# SAMA7D65D1GN2 register map
Vendor: Microchip Technology; Series: SAMA7D6; File version: 0
Registers are 32-bit, read-write, reset 0x0 unless marked. A register's access mark holds for its fields unless they carry their own. Offsets are from the block's base; [hi:lo] are bit positions; lines under a group give offsets from that group; {n}, {i} and the like mark numbered series.

## SYSCWP — System Controller Write Protection
Base 0xE001D900
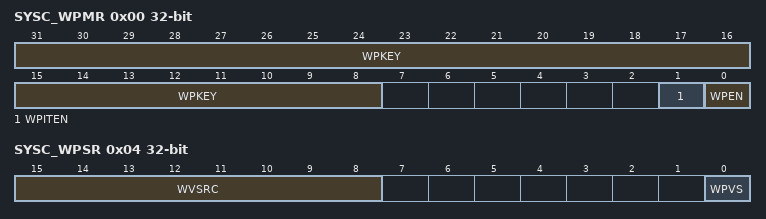
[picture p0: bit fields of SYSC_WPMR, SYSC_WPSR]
0x00 SYSC_WPMR — Write Protection Mode Register
  [31:8] WPKEY — Write Protection Key
    0x535943=PASSWD (Writing any other value in this field aborts the write operation of the WPEN and WPITEN bits. Always reads as 0.)
  [1] WPITEN — Write Protection RTC Interrupt Enable
    0=Disables the write protection of the RTC_IER/RTC_IDR configuration registers if WPKEY corresponds to 0x535943 ('SYC' in ASCII); 1=Enables the write protection of the RTC_IER/RTC_IDR configuration registers if WPKEY corresponds to 0x535943 ('SYC' in ASCII)
  [0] WPEN — Write Protection Enable
    0=Disables the write protection of the configuration registers if WPKEY corresponds to 0x535943 ('SYC' in ASCII); 1=Enables the write protection of the configuration registers if WPKEY corresponds to 0x535943 ('SYC' in ASCII)
0x04 SYSC_WPSR ro — Write Protection Status Register
  [15:8] WVSRC — Write Violation Source
  [0] WPVS — Write Protection Register Violation Status
    0=No write protection violation has occurred since the last read of SYSC_WPSR; 1=A write protection violation has occurred since the last read of SYSC_WPSR. The associated violation is reported into field WVSRC.

## TZAESBASC — AES Bridge Address Space Controller
Base 0xE2000000
{0x0+8i} TZAESBASC_RID[{i}] (i=0..7) group
  0x00 RBAR — Region Base Address
    [31:0] BASE
  0x04 RTAR — Region Top Address
    [31:0] TOP
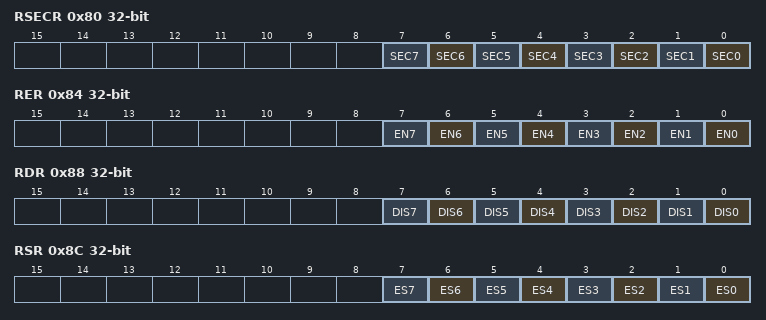
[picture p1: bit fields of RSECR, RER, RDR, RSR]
0x80 RSECR — Region Security
  [all] fields
    0=Region x is secure; 1=Region x is non-secure
  [n] SEC{n} (n=0..7) — Region {n} Security
0x84 RER wo — Region Enable
  [all] fields
    0=No effect; 1=Enables the corresponding region
  [n] EN{n} (n=0..7) — Region {n} Enable
0x88 RDR wo — Region Disable
  [all] fields
    0=No effect; 1=Disables the corresponding region
  [n] DIS{n} (n=0..7) — Region {n} Disable
0x8C RSR ro — Region Status
  [all] fields
    0=The corresponding region is disabled; 1=The corresponding region is enabled
  [n] ES{n} (n=0..7) — Region {n} Enable Status
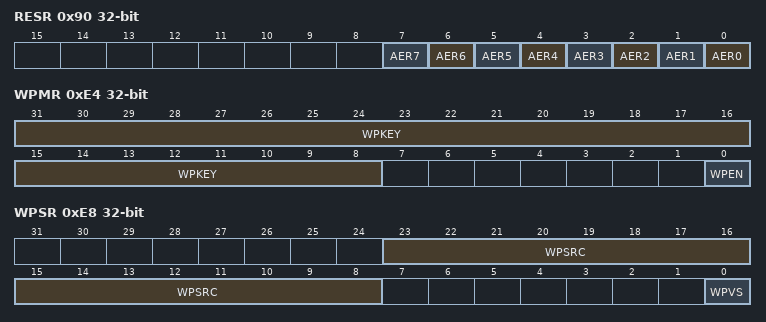
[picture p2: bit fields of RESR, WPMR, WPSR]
0x90 RESR ro — Region Error Status
  [all] fields
    0=No region x address error has occurred; 1=A region x address error has occurred since the last read of the Region Error Status register
  [n] AER{n} (n=0..7) — Region {n} Address Error
0x94 RSSR ro — Region Synchronization Status
  [0] SYNC
    0=Synchronization of the region configuration is done; 1=A region configuration is in progress
0xE4 WPMR — Write Protection Mode Register
  [31:8] WPKEY — Write Protection Key
    0x415343=PASSWD (Writing any other value in this field aborts the write operation of the WPEN bit. Always reads at 0.)
  [0] WPEN — Write Protection Enable
    0=Disables the write protection if WPKEY corresponds to 0x415343 ('ASC' in ASCII); 1=Enables the write protection. All accesses to configuration registers are canceled and generate an error in the TZAESBASC_WPSR register.
0xE8 WPSR ro — Write Protection Status Register
  [23:8] WPSRC — Write Protection Source
  [0] WPVS — Write Protection Violation Status
    0=No write protection violation has occurred since the last read of IP_Acronym_WPSR; 1=A write protection violation has occurred since the last read of IP_Acronym_WPSR. If this violation is an unauthorized attempt to write a protected register, the associated violation is reported into field WPSRC.

## TZPM — TrustZone Peripheral Manager
Base 0xE0010000
0x04 KEY
  [31:0] TZPMKEY — Write Protection Key
    0x12AC4B5D=PASSWD (Writing any other value in this field aborts the write operation of the TZPM_PIDRx registers. Always reads as 0.)
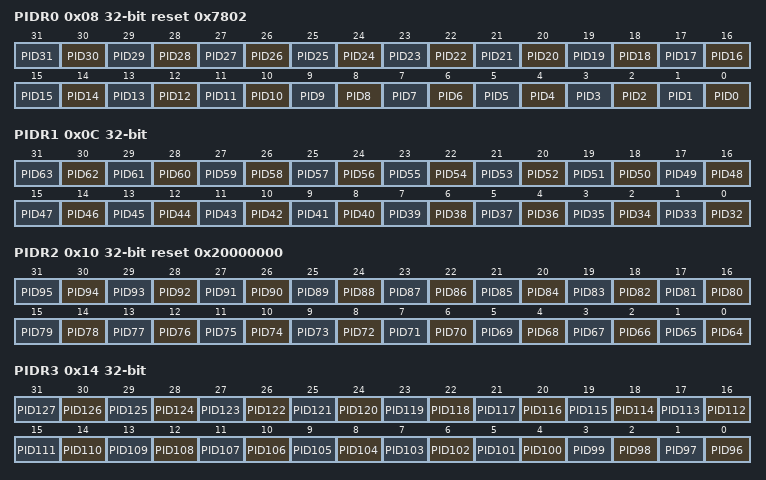
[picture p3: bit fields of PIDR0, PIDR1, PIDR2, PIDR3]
0x08 PIDR0 reset 0x7802 — Peripheral ID Register 0
  [all] fields
    0=Secure accesses only; 1=Non-secure accesses are allowed
  [n] PID{n} (n=0..31) — Peripheral ID {n} Security
0x0C PIDR1 — Peripheral ID Register 1
  [all] fields
    0=Secure accesses only; 1=Non-secure accesses are allowed
  [n-32] PID{n} (n=32..63) — Peripheral ID {n} Security
0x10 PIDR2 reset 0x20000000 — Peripheral ID Register 2
  [all] fields
    0=Secure accesses only; 1=Non-secure accesses are allowed
  [n-64] PID{n} (n=64..95) — Peripheral ID {n} Security
0x14 PIDR3 — Peripheral ID Register 3
  [all] fields
    0=Secure accesses only; 1=Non-secure accesses are allowed
  [n-96] PID{n} (n=96..127) — Peripheral ID {n} Security
